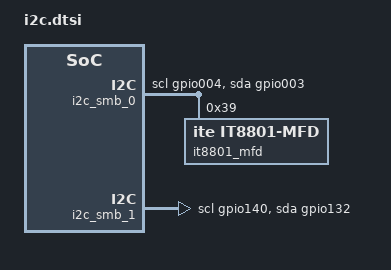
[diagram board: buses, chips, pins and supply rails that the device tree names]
/* Copyright 2025 The ChromiumOS Authors
 * Use of this source code is governed by a BSD-style license that can be
 * found in the LICENSE file.
 */

/* charger */
i2c_port_charger: &i2c_smb_0 {
	pinctrl-0 = <&i2c00_scl_gpio004 &i2c00_sda_gpio003>;
	pinctrl-names = "default";
	port-sel = <0>;
	status = "okay";
	scl-gpios = <MCHP_GPIO_DECODE_004 GPIO_OPEN_DRAIN>;
	sda-gpios = <MCHP_GPIO_DECODE_003 GPIO_OPEN_DRAIN>;


	it8801_mfd: it8801@39 {
		compatible = "ite,it8801-mfd";
		reg = <0x39>;
	};
};

/* typec-aic1-power */
i2c_port_pd1: &i2c_smb_1 {
	pinctrl-0 = <&i2c06_scl_gpio140 &i2c06_sda_gpio132>;
	pinctrl-names = "default";
	port-sel = <6>;
	status = "okay";
	scl-gpios = <MCHP_GPIO_DECODE_140 GPIO_OPEN_DRAIN>;
	sda-gpios = <MCHP_GPIO_DECODE_132 GPIO_OPEN_DRAIN>;
};

/ {
	i2c_port_pd2: placeholder_i2c_port_pd2 {

	};
	i2c_port_ish: placeholder_i2c_port_ish {

	};
};

#include "../rvp_i2c.dtsi"
#include "../rvp_imvp.dtsi"

&imvp_rt3645 {
	enable-gpios = <MCHP_GPIO_DECODE_226 GPIO_ACTIVE_HIGH>;
};

/delete-node/ &i2c_named_i2c_port_pd2;
/delete-node/ &i2c_named_i2c_port_ish;
